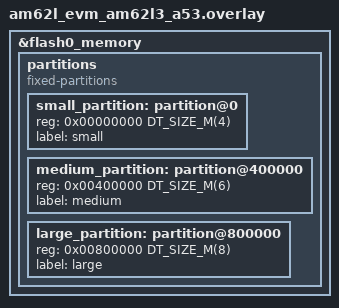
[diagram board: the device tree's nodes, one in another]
/*
 * SPDX-FileCopyrightText: 2026 Texas Instruments Incorporated
 *
 * SPDX-License-Identifier: Apache-2.0
 */

&flash0_memory {
	partitions {
		compatible = "fixed-partitions";
		#address-cells = <1>;
		#size-cells = <1>;

		small_partition: partition@0 {
			reg = <0x00000000 DT_SIZE_M(4)>;
			label = "small";
		};

		medium_partition: partition@400000 {
			reg = <0x00400000 DT_SIZE_M(6)>;
			label = "medium";
		};

		large_partition: partition@800000 {
			reg = <0x00800000 DT_SIZE_M(8)>;
			label = "large";
		};
	};
};
